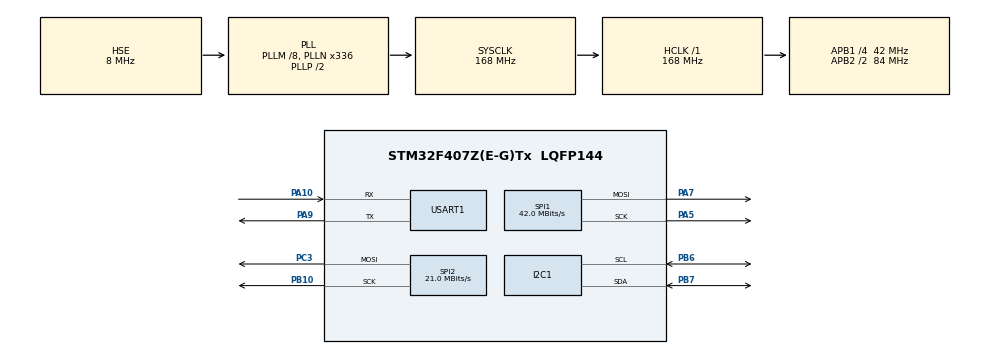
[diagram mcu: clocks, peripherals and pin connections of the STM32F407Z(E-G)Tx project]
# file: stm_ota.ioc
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Mcu.Family=STM32F4
Mcu.Name=STM32F407Z(E-G)Tx
Mcu.Package=LQFP144
NVIC.PriorityGroup=NVIC_PRIORITYGROUP_4
NVIC.TIM1_UP_TIM10_IRQn=true\:15\:0\:false\:false\:true\:false\:true\:true
NVIC.TimeBase=TIM1_UP_TIM10_IRQn
NVIC.TimeBaseIP=TIM1
PA10.Mode=Asynchronous
PA10.Signal=USART1_RX
PA13.Mode=Serial_Wire
PA13.Signal=SYS_JTMS-SWDIO
PA14.Mode=Serial_Wire
PA14.Signal=SYS_JTCK-SWCLK
PA5.Mode=TX_Only_Simplex_Unidirect_Master
PA5.Signal=SPI1_SCK
PA7.Mode=TX_Only_Simplex_Unidirect_Master
PA7.Signal=SPI1_MOSI
PA9.Mode=Asynchronous
PA9.Signal=USART1_TX
PB10.Mode=TX_Only_Simplex_Unidirect_Master
PB10.Signal=SPI2_SCK
PB6.Mode=I2C
PB6.Signal=I2C1_SCL
PB7.Mode=I2C
PB7.Signal=I2C1_SDA
PC14-OSC32_IN.Mode=LSE-External-Oscillator
PC14-OSC32_IN.Signal=RCC_OSC32_IN
PC15-OSC32_OUT.Mode=LSE-External-Oscillator
PC15-OSC32_OUT.Signal=RCC_OSC32_OUT
PC3.Mode=TX_Only_Simplex_Unidirect_Master
PC3.Signal=SPI2_MOSI
PH0-OSC_IN.Mode=HSE-External-Oscillator
PH0-OSC_IN.Signal=RCC_OSC_IN
PH1-OSC_OUT.Mode=HSE-External-Oscillator
PH1-OSC_OUT.Signal=RCC_OSC_OUT
ProjectManager.HeapSize=0x200
ProjectManager.StackSize=0x400
ProjectManager.TargetToolchain=CMake
RCC.48MHZClocksFreq_Value=84000000
RCC.AHBFreq_Value=168000000
RCC.APB1CLKDivider=RCC_HCLK_DIV4
RCC.APB1Freq_Value=42000000
RCC.APB1TimFreq_Value=84000000
RCC.APB2CLKDivider=RCC_HCLK_DIV2
RCC.APB2Freq_Value=84000000
RCC.APB2TimFreq_Value=168000000
RCC.CortexFreq_Value=168000000
RCC.HCLKFreq_Value=168000000
RCC.HSE_VALUE=8000000
RCC.HSI_VALUE=16000000
RCC.PLLM=8
RCC.PLLN=336
RCC.PLLSourceVirtual=RCC_PLLSOURCE_HSE
RCC.RCC_RTC_Clock_Source=RCC_RTCCLKSOURCE_LSE
RCC.RCC_RTC_Clock_SourceVirtual=RCC_RTCCLKSOURCE_LSE
RCC.SYSCLKFreq_VALUE=168000000
RCC.SYSCLKSource=RCC_SYSCLKSOURCE_PLLCLK
RCC.VCOOutputFreq_Value=336000000
SPI1.BaudRatePrescaler=SPI_BAUDRATEPRESCALER_2
SPI1.CalculateBaudRate=42.0 MBits/s
SPI1.Direction=SPI_DIRECTION_2LINES
SPI1.Mode=SPI_MODE_MASTER
SPI1.VirtualType=VM_MASTER
SPI2.BaudRatePrescaler=SPI_BAUDRATEPRESCALER_2
SPI2.CalculateBaudRate=21.0 MBits/s
SPI2.Direction=SPI_DIRECTION_2LINES
SPI2.Mode=SPI_MODE_MASTER
SPI2.VirtualType=VM_MASTER
USART1.VirtualMode=VM_ASYNC
VP_RTC_VS_RTC_Activate.Mode=RTC_Enabled
VP_SYS_VS_tim1.Mode=TIM1
board=custom

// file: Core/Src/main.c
/* USER CODE BEGIN Header */
/**
  ******************************************************************************
  * @file           : main.c
  * @brief          : Main program body
  ******************************************************************************
  * @attention
  *
  * Copyright (c) 2026 STMicroelectronics.
  * All rights reserved.
  *
  * This software is licensed under terms that can be found in the LICENSE file
  * in the root directory of this software component.
  * If no LICENSE file comes with this software, it is provided AS-IS.
  *
  ******************************************************************************
  */
/* USER CODE END Header */
#include "main.h"
#include "i2c.h"
#include "rtc.h"
#include "spi.h"
#include "usart.h"
#include "gpio.h"

/* USER CODE BEGIN Includes */
#include "ota_boot.h"
/* USER CODE END Includes */

void SystemClock_Config(void);

int main(void)
{

  /* MCU Configuration--------------------------------------------------------*/

  /* Reset of all peripherals, Initializes the Flash interface and the Systick. */
  HAL_Init();

  /* Configure the system clock */
  SystemClock_Config();

  /* USER CODE BEGIN SysInit */
  /* 打开 PWR 时钟并解除备份域写保护。两件事都必须在这里做，且都在 MX_RTC_Init()
   * 之前：
   *   1) RTC 寄存器（含 PRER）属于备份域。DBP=0 时写进去是无效的，MX_RTC_Init()
   *      会在等 INITF 时超时，进而 Error_Handler() 死循环——首次上电（备份域刚被
   *      复位、RTC 日历尚未初始化）就必然踩上。
   *   2) Bootloader 用 RTC->BKP0R 传递「App 请求升级」的标志，读写同样需要它。
   * HAL_RTC_Init() 自己不开这两个开关（见 stm32f4xx_hal_rtc.c 的 RTC_Init 说明），
   * 所以必须由应用来做。 */
  __HAL_RCC_PWR_CLK_ENABLE();
  HAL_PWR_EnableBkUpAccess();
  /* USER CODE END SysInit */

  /* Initialize all configured peripherals */
  MX_GPIO_Init();
  MX_I2C1_Init();
  MX_RTC_Init();
  MX_SPI1_Init();
  MX_SPI2_Init();
  MX_USART1_UART_Init();
  /* USER CODE BEGIN 2 */

  /* Bootloader 主流程。正常情况不会返回：要么跳进 0x08010000 的 App，
   * 要么停在这里反复等 OTA_START。 */
  ota_boot_run();
  /* USER CODE END 2 */

  /* Infinite loop */
  while (1)
  {

  }
}

void SystemClock_Config(void)
{
  RCC_OscInitTypeDef RCC_OscInitStruct = {0};
  RCC_ClkInitTypeDef RCC_ClkInitStruct = {0};

  /** Configure the main internal regulator output voltage
  */
  __HAL_RCC_PWR_CLK_ENABLE();
  __HAL_PWR_VOLTAGESCALING_CONFIG(PWR_REGULATOR_VOLTAGE_SCALE1);

  /** Initializes the RCC Oscillators according to the specified parameters
  * in the RCC_OscInitTypeDef structure.
  */
  RCC_OscInitStruct.OscillatorType = RCC_OSCILLATORTYPE_HSE|RCC_OSCILLATORTYPE_LSE;
  RCC_OscInitStruct.HSEState = RCC_HSE_ON;
  RCC_OscInitStruct.LSEState = RCC_LSE_ON;
  RCC_OscInitStruct.PLL.PLLState = RCC_PLL_ON;
  RCC_OscInitStruct.PLL.PLLSource = RCC_PLLSOURCE_HSE;
  RCC_OscInitStruct.PLL.PLLM = 8;
  RCC_OscInitStruct.PLL.PLLN = 336;
  RCC_OscInitStruct.PLL.PLLP = RCC_PLLP_DIV2;
  RCC_OscInitStruct.PLL.PLLQ = 4;
  if (HAL_RCC_OscConfig(&RCC_OscInitStruct) != HAL_OK)
  {
    Error_Handler();
  }

  /** Initializes the CPU, AHB and APB buses clocks
  */
  RCC_ClkInitStruct.ClockType = RCC_CLOCKTYPE_HCLK|RCC_CLOCKTYPE_SYSCLK
                              |RCC_CLOCKTYPE_PCLK1|RCC_CLOCKTYPE_PCLK2;
  RCC_ClkInitStruct.SYSCLKSource = RCC_SYSCLKSOURCE_PLLCLK;
  RCC_ClkInitStruct.AHBCLKDivider = RCC_SYSCLK_DIV1;
  RCC_ClkInitStruct.APB1CLKDivider = RCC_HCLK_DIV4;
  RCC_ClkInitStruct.APB2CLKDivider = RCC_HCLK_DIV2;

  if (HAL_RCC_ClockConfig(&RCC_ClkInitStruct, FLASH_LATENCY_5) != HAL_OK)
  {
    Error_Handler();
  }
}

void HAL_TIM_PeriodElapsedCallback(TIM_HandleTypeDef *htim)
{
  if (htim->Instance == TIM1)
  {
    HAL_IncTick();
  }
}

void Error_Handler(void)
{
  __disable_irq();
  while (1)
  {
  }
}
